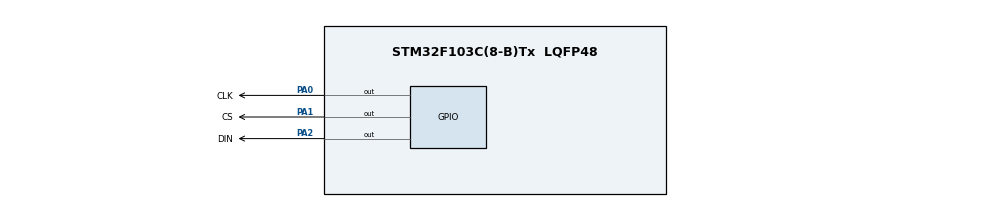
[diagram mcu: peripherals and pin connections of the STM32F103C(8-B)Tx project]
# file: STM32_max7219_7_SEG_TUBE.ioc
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Mcu.Family=STM32F1
Mcu.Name=STM32F103C(8-B)Tx
Mcu.Package=LQFP48
NVIC.PriorityGroup=NVIC_PRIORITYGROUP_4
NVIC.TIM2_IRQn=true\:0\:0\:false\:false\:true
PA0-WKUP.GPIO_Label=CLK
PA0-WKUP.Signal=GPIO_Output
PA1.GPIO_Label=CS
PA1.Signal=GPIO_Output
PA13.Mode=Serial_Wire
PA13.Signal=SYS_JTMS-SWDIO
PA14.Mode=Serial_Wire
PA14.Signal=SYS_JTCK-SWCLK
PA2.GPIO_Label=DIN
PA2.Signal=GPIO_Output
ProjectManager.HeapSize=0x200
ProjectManager.StackSize=0x400
ProjectManager.TargetToolchain=Makefile
RCC.APB1CLKDivider=RCC_HCLK_DIV4
RCC.APB1Freq_Value=2000000
RCC.APB1TimFreq_Value=4000000
RCC.APB2Freq_Value=8000000
RCC.APB2TimFreq_Value=8000000
TIM2.Period=49
TIM2.Prescaler=7999
TIM2.TIM_MasterOutputTrigger=TIM_TRGO_UPDATE
VP_TIM2_VS_ClockSourceINT.Mode=Internal
board=STM32_max7219_7_SEG_TUBE

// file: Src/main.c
/**
  ******************************************************************************
  * File Name          : main.c
  * Description        : Main program body
  ******************************************************************************
  ** This notice applies to any and all portions of this file
  * that are not between comment pairs USER CODE BEGIN and
  * USER CODE END. Other portions of this file, whether
  * inserted by the user or by software development tools
  * are owned by their respective copyright owners.
  *
  * COPYRIGHT(c) 2018 STMicroelectronics
  *
  * Redistribution and use in source and binary forms, with or without modification,
  * are permitted provided that the following conditions are met:
  *   1. Redistributions of source code must retain the above copyright notice,
  *      this list of conditions and the following disclaimer.
  *   2. Redistributions in binary form must reproduce the above copyright notice,
  *      this list of conditions and the following disclaimer in the documentation
  *      and/or other materials provided with the distribution.
  *   3. Neither the name of STMicroelectronics nor the names of its contributors
  *      may be used to endorse or promote products derived from this software
  *      without specific prior written permission.
  *
  * THIS SOFTWARE IS PROVIDED BY THE COPYRIGHT HOLDERS AND CONTRIBUTORS "AS IS"
  * AND ANY EXPRESS OR IMPLIED WARRANTIES, INCLUDING, BUT NOT LIMITED TO, THE
  * IMPLIED WARRANTIES OF MERCHANTABILITY AND FITNESS FOR A PARTICULAR PURPOSE ARE
  * DISCLAIMED. IN NO EVENT SHALL THE COPYRIGHT HOLDER OR CONTRIBUTORS BE LIABLE
  * FOR ANY DIRECT, INDIRECT, INCIDENTAL, SPECIAL, EXEMPLARY, OR CONSEQUENTIAL
  * DAMAGES (INCLUDING, BUT NOT LIMITED TO, PROCUREMENT OF SUBSTITUTE GOODS OR
  * SERVICES; LOSS OF USE, DATA, OR PROFITS; OR BUSINESS INTERRUPTION) HOWEVER
  * CAUSED AND ON ANY THEORY OF LIABILITY, WHETHER IN CONTRACT, STRICT LIABILITY,
  * OR TORT (INCLUDING NEGLIGENCE OR OTHERWISE) ARISING IN ANY WAY OUT OF THE USE
  * OF THIS SOFTWARE, EVEN IF ADVISED OF THE POSSIBILITY OF SUCH DAMAGE.
  *
  ******************************************************************************
  */
#include "main.h"
#include "stm32f1xx_hal.h"

/* USER CODE BEGIN Includes */
#include "max7219display.c"
/* memory and peripheral start addresses */
/* pin definitions */
#include "pins_ext.h"

// #define CLK_Pin GPIO_PIN_0
// #define CLK_GPIO_Port GPIOA
// #define CS_Pin GPIO_PIN_1
// #define CS_GPIO_Port GPIOA
// #define DIN_Pin GPIO_PIN_2
// #define DIN_GPIO_Port GPIOA

/* USER CODE END Includes */

TIM_HandleTypeDef htim2;

/* USER CODE BEGIN PV */
/* Private variables ---------------------------------------------------------*/
long num;
uint8_t tim2_counter;
float tim2_Period;
/* USER CODE END PV */

void SystemClock_Config(void);
static void MX_GPIO_Init(void);
static void MX_TIM2_Init(void);

/* USER CODE BEGIN PFP */
/* Private function prototypes -----------------------------------------------*/
__STATIC_INLINE void DelayMicro(uint32_t volatile micros)
{
  micros *=(SystemCoreClock/1000000)/5;
  while(micros--);
}

/* USER CODE END PFP */

/* USER CODE BEGIN 0 */

long num;
void test_display(void);
void scroll_digits(void);

// showNumberDec(num, leading_zero, length, pos);

void test_display(void)
{
  showNumberDec(12345678, 1, 8, 0);
  HAL_Delay(500);
  showNumberDec(87654321, 1, 8, 0);
  HAL_Delay(500);
  showNumberDec(88888888, 1, 8, 0);
  HAL_Delay(500);
  num = 0L;
}

void scroll_digits(void)
{
  showNumberDec(num, 0, 8, 0);
  HAL_Delay(10);
  if (++num > 99999999)
    num = 0L;
}

/* USER CODE END 0 */

int main(void)
{

  /* USER CODE BEGIN 1 */
  MAX7219_init();
  /* USER CODE END 1 */

  /* MCU Configuration----------------------------------------------------------*/

  /* Reset of all peripherals, Initializes the Flash interface and the Systick. */
  HAL_Init();

  /* Configure the system clock */
  SystemClock_Config();

  /* Initialize all configured peripherals */
  MX_GPIO_Init();
  MX_TIM2_Init();

  /* USER CODE BEGIN 2 */
  //pin_mode(GPIOB, GPIO_PIN_12, GPIO_MODE_INPUT);
  pin_mode(CLK_GPIO_Port, CLK_Pin, GPIO_MODE_OUTPUT_PP); // _OD/_PP "Open Drain/Push Pull"
  pin_mode(CS_GPIO_Port, CS_Pin, GPIO_MODE_OUTPUT_PP); // _OD/_PP "Open Drain/Push Pull"
  pin_mode(DIN_GPIO_Port, DIN_Pin, GPIO_MODE_OUTPUT_PP); // _OD/_PP "Open Drain/Push Pull"

  /* USER CODE END 2 */

  /* Infinite loop */
  while (1)
  {

  /* USER CODE BEGIN 3 */
    scroll_digits();
  }
  /* USER CODE END 3 */

}

/** System Clock Configuration
*/
void SystemClock_Config(void)
{

  RCC_OscInitTypeDef RCC_OscInitStruct;
  RCC_ClkInitTypeDef RCC_ClkInitStruct;

    /**Initializes the CPU, AHB and APB busses clocks
    */
  RCC_OscInitStruct.OscillatorType = RCC_OSCILLATORTYPE_HSI;
  RCC_OscInitStruct.HSIState = RCC_HSI_ON;
  RCC_OscInitStruct.HSICalibrationValue = 16;
  RCC_OscInitStruct.PLL.PLLState = RCC_PLL_NONE;
  if (HAL_RCC_OscConfig(&RCC_OscInitStruct) != HAL_OK)
  {
    _Error_Handler(__FILE__, __LINE__);
  }

    /**Initializes the CPU, AHB and APB busses clocks
    */
  RCC_ClkInitStruct.ClockType = RCC_CLOCKTYPE_HCLK|RCC_CLOCKTYPE_SYSCLK
                              |RCC_CLOCKTYPE_PCLK1|RCC_CLOCKTYPE_PCLK2;
  RCC_ClkInitStruct.SYSCLKSource = RCC_SYSCLKSOURCE_HSI;
  RCC_ClkInitStruct.AHBCLKDivider = RCC_SYSCLK_DIV1;
  RCC_ClkInitStruct.APB1CLKDivider = RCC_HCLK_DIV4;
  RCC_ClkInitStruct.APB2CLKDivider = RCC_HCLK_DIV1;

  if (HAL_RCC_ClockConfig(&RCC_ClkInitStruct, FLASH_LATENCY_0) != HAL_OK)
  {
    _Error_Handler(__FILE__, __LINE__);
  }

    /**Configure the Systick interrupt time
    */
  HAL_SYSTICK_Config(HAL_RCC_GetHCLKFreq()/1000);

    /**Configure the Systick
    */
  HAL_SYSTICK_CLKSourceConfig(SYSTICK_CLKSOURCE_HCLK);

  /* SysTick_IRQn interrupt configuration */
  HAL_NVIC_SetPriority(SysTick_IRQn, 0, 0);
}

/* TIM2 init function */
static void MX_TIM2_Init(void)
{

  TIM_ClockConfigTypeDef sClockSourceConfig;
  TIM_MasterConfigTypeDef sMasterConfig;

  htim2.Instance = TIM2;
  htim2.Init.Prescaler = 7999;
  htim2.Init.CounterMode = TIM_COUNTERMODE_UP;
  htim2.Init.Period = 49;
  htim2.Init.ClockDivision = TIM_CLOCKDIVISION_DIV1;
  htim2.Init.AutoReloadPreload = TIM_AUTORELOAD_PRELOAD_DISABLE;
  if (HAL_TIM_Base_Init(&htim2) != HAL_OK)
  {
    _Error_Handler(__FILE__, __LINE__);
  }

  sClockSourceConfig.ClockSource = TIM_CLOCKSOURCE_INTERNAL;
  if (HAL_TIM_ConfigClockSource(&htim2, &sClockSourceConfig) != HAL_OK)
  {
    _Error_Handler(__FILE__, __LINE__);
  }

  sMasterConfig.MasterOutputTrigger = TIM_TRGO_UPDATE;
  sMasterConfig.MasterSlaveMode = TIM_MASTERSLAVEMODE_DISABLE;
  if (HAL_TIMEx_MasterConfigSynchronization(&htim2, &sMasterConfig) != HAL_OK)
  {
    _Error_Handler(__FILE__, __LINE__);
  }

}

/** Configure pins as
        * Analog
        * Input
        * Output
        * EVENT_OUT
        * EXTI
*/
static void MX_GPIO_Init(void)
{

  GPIO_InitTypeDef GPIO_InitStruct;

  /* GPIO Ports Clock Enable */
  __HAL_RCC_GPIOA_CLK_ENABLE();

  /*Configure GPIO pin Output Level */
  HAL_GPIO_WritePin(GPIOA, CLK_Pin|CS_Pin|DIN_Pin, GPIO_PIN_RESET);

  /*Configure GPIO pins : CLK_Pin CS_Pin DIN_Pin */
  GPIO_InitStruct.Pin = CLK_Pin|CS_Pin|DIN_Pin;
  GPIO_InitStruct.Mode = GPIO_MODE_OUTPUT_PP;
  GPIO_InitStruct.Speed = GPIO_SPEED_FREQ_LOW;
  HAL_GPIO_Init(GPIOA, &GPIO_InitStruct);

}

void _Error_Handler(char * file, int line)
{
  while(1)
  {
  }
}

/************************ (C) COPYRIGHT STMicroelectronics *****END OF FILE****/
